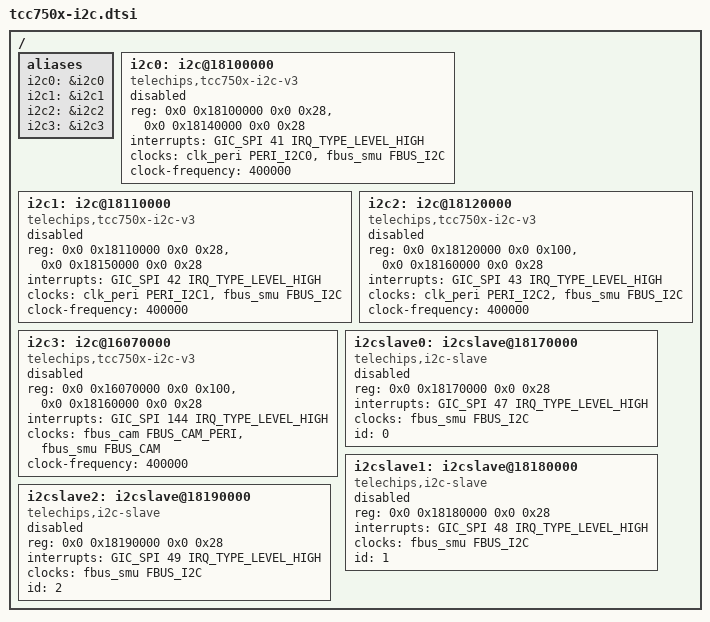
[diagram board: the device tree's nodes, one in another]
// SPDX-License-Identifier: (GPL-2.0-or-later OR MIT)
/*
 * Copyright (C) 2023 Telechips Inc.
 */

#include <dt-bindings/clock/telechips,tcc750x-clks.h>
#include <dt-bindings/interrupt-controller/arm-gic.h>

/ {
	aliases: aliases {
		i2c0  = &i2c0;
		i2c1  = &i2c1;
		i2c2  = &i2c2;
		i2c3  = &i2c3;
	};

	i2c0: i2c@18100000 {
		compatible = "telechips,tcc750x-i2c-v3";
		reg = <0x0 0x18100000 0x0 0x28>,
		      <0x0 0x18140000 0x0 0x28>;
		interrupts = <GIC_SPI 41 IRQ_TYPE_LEVEL_HIGH>;
		#address-cells = <1>;
		#size-cells = <0>;
		clocks = <&clk_peri PERI_I2C0 &fbus_smu FBUS_I2C>;
		clock-frequency = <400000>;
		status = "disabled";
	};

	i2c1: i2c@18110000 {
		compatible = "telechips,tcc750x-i2c-v3";
		reg = <0x0 0x18110000 0x0 0x28>,
		      <0x0 0x18150000 0x0 0x28>;
		interrupts = <GIC_SPI 42 IRQ_TYPE_LEVEL_HIGH>;
		#address-cells = <1>;
		#size-cells = <0>;
		clocks = <&clk_peri PERI_I2C1 &fbus_smu FBUS_I2C>;
		clock-frequency = <400000>;
		status = "disabled";
	};

	i2c2: i2c@18120000 {
		compatible = "telechips,tcc750x-i2c-v3";
		reg = <0x0 0x18120000 0x0 0x100>,
		      <0x0 0x18160000 0x0 0x28>;
		interrupts = <GIC_SPI 43 IRQ_TYPE_LEVEL_HIGH>;
		#address-cells = <1>;
		#size-cells = <0>;
		clocks = <&clk_peri PERI_I2C2 &fbus_smu FBUS_I2C>;
		clock-frequency = <400000>;
		status = "disabled";
	};

	i2c3: i2c@16070000 {
		compatible = "telechips,tcc750x-i2c-v3";
		reg = <0x0 0x16070000 0x0 0x100>,
		      <0x0 0x18160000 0x0 0x28>;
		interrupts = <GIC_SPI 144 IRQ_TYPE_LEVEL_HIGH>;
		#address-cells = <1>;
		#size-cells = <0>;
		clocks = <&fbus_cam FBUS_CAM_PERI &fbus_smu FBUS_CAM>;
		clock-frequency = <400000>;
		status = "disabled";
	};

	i2cslave0: i2cslave@18170000 {
		compatible = "telechips,i2c-slave";
		reg = <0x0 0x18170000 0x0 0x28>;
		interrupts = <GIC_SPI 47 IRQ_TYPE_LEVEL_HIGH>;
		#address-cells = <1>;
		#size-cells = <0>;
		clocks = <&fbus_smu FBUS_I2C>;
		id = <0>;
		status = "disabled";

		/* USE DMA-engine */
		//dmas = <&dma0 0 0>, <&dma0 3 1>;
		//dma-names = "tx", "rx";
	};

	i2cslave1: i2cslave@18180000 {
		compatible = "telechips,i2c-slave";
		reg = <0x0 0x18180000 0x0 0x28>;
		interrupts = <GIC_SPI 48 IRQ_TYPE_LEVEL_HIGH>;
		#address-cells = <1>;
		#size-cells = <0>;
		clocks = <&fbus_smu FBUS_I2C>;
		id = <1>;
		status = "disabled";

		/* USE DMA-engine */
		//dmas = <&dma0 1 0>, <&dma0 4 1>;
		//dma-names = "tx", "rx";
	};

	i2cslave2: i2cslave@18190000 {
		compatible = "telechips,i2c-slave";
		reg = <0x0 0x18190000 0x0 0x28>;
		interrupts = <GIC_SPI 49 IRQ_TYPE_LEVEL_HIGH>;
		#address-cells = <1>;
		#size-cells = <0>;
		clocks = <&fbus_smu FBUS_I2C>;
		id = <2>;
		status = "disabled";

		/* USE DMA-engine */
		//dmas = <&dma0 2 0>, <&dma0 5 1>;
		//dma-names = "tx", "rx";
	};

};
